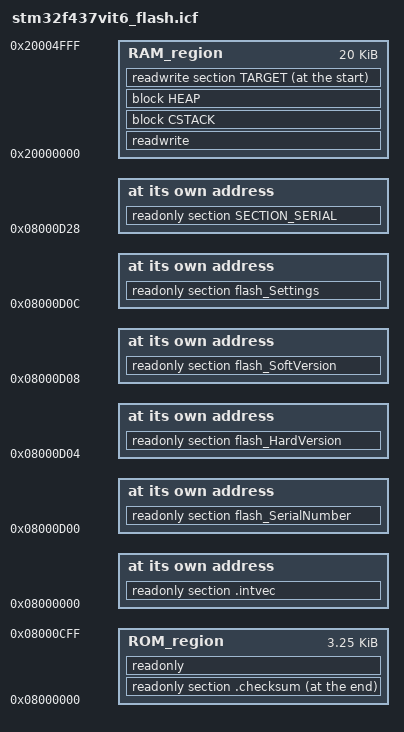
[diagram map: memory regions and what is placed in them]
/*###ICF### Section handled by ICF editor, don't touch! ****/
/*-Editor annotation file-*/
/* IcfEditorFile="$TOOLKIT_DIR$\config\ide\IcfEditor\cortex_v1_0.xml" */
/*-Specials-*/
define symbol __ICFEDIT_intvec_start__ = 0x08000000;
/*-Memory Regions-*/
define symbol __ICFEDIT_region_ROM_start__ = 0x08000000 ;
define symbol __ICFEDIT_region_ROM_end__   = 0x08000CFF;                 // Max 0x0801FFFF
define symbol __ICFEDIT_region_RAM_start__ = 0x20000000;
define symbol __ICFEDIT_region_RAM_end__   = 0x20004FFF;
/*-Sizes-*/
define symbol __ICFEDIT_size_cstack__ = 0x600;
define symbol __ICFEDIT_size_heap__   = 0x200;
/**** End of ICF editor section. ###ICF###*/

define memory mem with size = 4G;
define region ROM_region   = mem:[from __ICFEDIT_region_ROM_start__   to __ICFEDIT_region_ROM_end__];
define region RAM_region   = mem:[from __ICFEDIT_region_RAM_start__   to __ICFEDIT_region_RAM_end__];

define block CSTACK    with alignment = 8, size = __ICFEDIT_size_cstack__   { };
define block HEAP      with alignment = 8, size = __ICFEDIT_size_heap__     { };
 
initialize by copy { readwrite };
do not initialize  { section .noinit };

place at address mem:__ICFEDIT_intvec_start__ { readonly section .intvec };
place at end of ROM_region { readonly section .checksum };

place in ROM_region   { readonly };
place in RAM_region   { readwrite, block CSTACK, block HEAP };

place at start of RAM_region { readwrite section TARGET };
do not initialize  { section TARGET };

place at address mem:0x8000D00 {readonly section flash_SerialNumber};
place at address mem:0x8000D04 {readonly section flash_HardVersion};
place at address mem:0x8000D08 {readonly section flash_SoftVersion};
place at address mem:0x8000D0C {readonly section flash_Settings};
place at address mem:0x8000D28 {readonly section SECTION_SERIAL};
